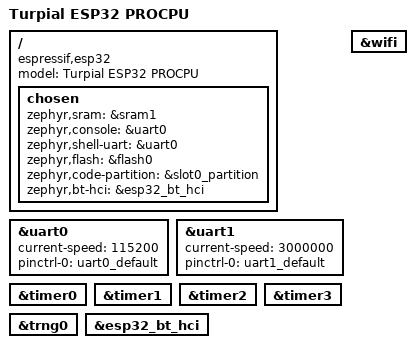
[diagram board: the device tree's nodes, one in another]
/*
 * Copyright (c) 2026 Jean-Pierre De Jesus DIAZ <me@jeandudey.tech>
 *
 * SPDX-License-Identifier: Apache-2.0
 */

/dts-v1/;

#include <espressif/esp32/esp32_wrover_e_n4r8.dtsi>
#include "turpial-esp32-pinctrl.dtsi"
#include <espressif/partitions_0x1000_amp.dtsi>

/ {
	model = "Turpial ESP32 PROCPU";
	compatible = "espressif,esp32";

	chosen {
		zephyr,sram = &sram1;
		zephyr,console = &uart0;
		zephyr,shell-uart = &uart0;
		zephyr,flash = &flash0;
		zephyr,code-partition = &slot0_partition;
		zephyr,bt-hci = &esp32_bt_hci;
	};
};

&uart0 {
	status = "okay";
	current-speed = <115200>;
	pinctrl-0 = <&uart0_default>;
	pinctrl-names = "default";
};

&uart1 {
	status = "okay";
	current-speed = <3000000>;
	pinctrl-0 = <&uart1_default>;
	pinctrl-names = "default";
};

&timer0 {
	status = "okay";
};

&timer1 {
	status = "okay";
};

&timer2 {
	status = "okay";
};

&timer3 {
	status = "okay";
};

&trng0 {
	status = "okay";
};

&esp32_bt_hci {
	status = "okay";
};

&wifi {
	status = "okay";
};
